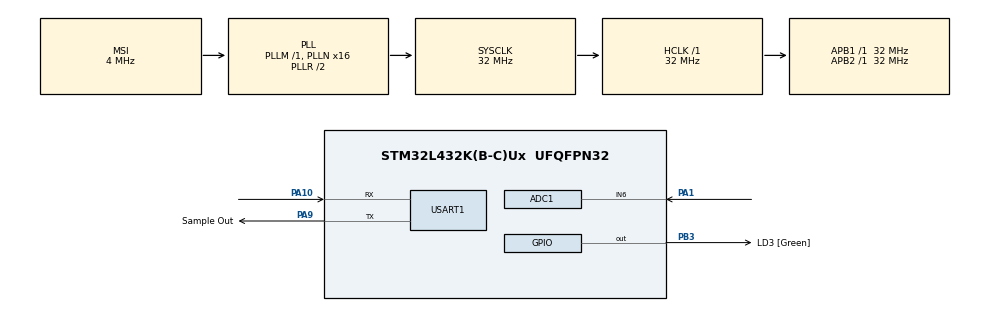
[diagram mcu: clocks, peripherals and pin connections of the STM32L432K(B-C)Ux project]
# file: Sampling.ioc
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ADC1.Channel-0\#ChannelRegularConversion=ADC_CHANNEL_6
ADC1.ExternalTrigConv=ADC_EXTERNALTRIG_T2_TRGO
ADC1.NbrOfConversionFlag=1
ADC1.OffsetNumber-0\#ChannelRegularConversion=ADC_OFFSET_NONE
ADC1.Rank-0\#ChannelRegularConversion=1
ADC1.Resolution=ADC_RESOLUTION_8B
ADC1.SamplingTime-0\#ChannelRegularConversion=ADC_SAMPLETIME_2CYCLES_5
ADC1.master=1
Mcu.Family=STM32L4
Mcu.Name=STM32L432K(B-C)Ux
Mcu.Package=UFQFPN32
NVIC.ADC1_IRQn=true\:0\:0\:false\:false\:true\:true\:true\:true
NVIC.PriorityGroup=NVIC_PRIORITYGROUP_4
NVIC.TIM2_IRQn=true\:0\:0\:false\:false\:true\:true\:true\:true
NVIC.USART1_IRQn=true\:0\:0\:false\:false\:true\:true\:true\:true
PA0.GPIO_Label=MCO [High speed clock in]
PA0.Mode=HSE-External-Clock-Source-for-LittleOrca
PA0.Signal=RCC_CK_IN
PA1.Signal=ADCx_IN6
PA10.Mode=Asynchronous
PA10.Signal=USART1_RX
PA13\ (JTMS-SWDIO).GPIO_Label=SWDIO
PA13\ (JTMS-SWDIO).Mode=Serial_Wire
PA13\ (JTMS-SWDIO).Signal=SYS_JTMS-SWDIO
PA14\ (JTCK-SWCLK).GPIO_Label=SWCLK
PA14\ (JTCK-SWCLK).Mode=Serial_Wire
PA14\ (JTCK-SWCLK).Signal=SYS_JTCK-SWCLK
PA15\ (JTDI).GPIO_Label=VCP_RX
PA15\ (JTDI).Signal=USART2_RX
PA2.GPIO_Label=VCP_TX
PA2.Signal=USART2_TX
PA9.GPIO_Label=Sample Out
PA9.Mode=Asynchronous
PA9.Signal=USART1_TX
PB3\ (JTDO-TRACESWO).GPIO_Label=LD3 [Green]
PB3\ (JTDO-TRACESWO).Signal=GPIO_Output
PC14-OSC32_IN\ (PC14).Mode=LSE-External-Oscillator
PC14-OSC32_IN\ (PC14).Signal=RCC_OSC32_IN
PC15-OSC32_OUT\ (PC15).Mode=LSE-External-Oscillator
PC15-OSC32_OUT\ (PC15).Signal=RCC_OSC32_OUT
ProjectManager.HeapSize=0x200
ProjectManager.StackSize=0x400
ProjectManager.TargetToolchain=STM32CubeIDE
RCC.ADCFreq_Value=32000000
RCC.AHBFreq_Value=32000000
RCC.APB1Freq_Value=32000000
RCC.APB1TimFreq_Value=32000000
RCC.APB2Freq_Value=32000000
RCC.APB2TimFreq_Value=32000000
RCC.CortexFreq_Value=32000000
RCC.HCLKFreq_Value=32000000
RCC.HSE_VALUE=8000000
RCC.HSI16_VALUE=16000000
RCC.HSI48_VALUE=48000000
RCC.HSI_VALUE=16000000
RCC.MSI_VALUE=4000000
RCC.PLLMUL=RCC_PLLMUL_4
RCC.PLLN=16
RCC.PLLSAI1N=16
RCC.SYSCLKFreq_VALUE=32000000
RCC.SYSCLKSource=RCC_SYSCLKSOURCE_PLLCLK
RCC.USBFreq_Value=32000000
RCC.VCOOutputFreq_Value=64000000
SH.ADCx_IN6.0=ADC1_IN6,IN6-Single-Ended
TIM2.Period=19
TIM2.Prescaler=719
TIM2.TIM_MasterOutputTrigger=TIM_TRGO_UPDATE
USART1.VirtualMode-Asynchronous=VM_ASYNC
VP_TIM2_VS_ClockSourceINT.Mode=Internal
board=NUCLEO-L432KC

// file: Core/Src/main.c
/* USER CODE BEGIN Header */
/**
  ******************************************************************************
  * @file           : main.c
  * @brief          : Main program body
  ******************************************************************************
  * @attention
  *
  * Copyright (c) 2025 STMicroelectronics.
  * All rights reserved.
  *
  * This software is licensed under terms that can be found in the LICENSE file
  * in the root directory of this software component.
  * If no LICENSE file comes with this software, it is provided AS-IS.
  *
  ******************************************************************************
  */
/* USER CODE END Header */
#include "main.h"

ADC_HandleTypeDef hadc1;

TIM_HandleTypeDef htim2;

UART_HandleTypeDef huart1;

void SystemClock_Config(void);
static void MX_GPIO_Init(void);
static void MX_TIM2_Init(void);
static void MX_ADC1_Init(void);
static void MX_USART1_UART_Init(void);

int main(void)
{

  /* MCU Configuration--------------------------------------------------------*/

  /* Reset of all peripherals, Initializes the Flash interface and the Systick. */
  HAL_Init();

  /* Configure the system clock */
  SystemClock_Config();

  /* Initialize all configured peripherals */
  MX_GPIO_Init();
  MX_TIM2_Init();
  MX_ADC1_Init();
  MX_USART1_UART_Init();
  /* USER CODE BEGIN 2 */
    HAL_TIM_Base_Start(&htim2);
    HAL_ADC_Start_IT(&hadc1);
  /* USER CODE END 2 */

  /* Infinite loop */
    while (1) {

    }
}

void SystemClock_Config(void)
{
  RCC_OscInitTypeDef RCC_OscInitStruct = {0};
  RCC_ClkInitTypeDef RCC_ClkInitStruct = {0};

  /** Configure the main internal regulator output voltage
  */
  if (HAL_PWREx_ControlVoltageScaling(PWR_REGULATOR_VOLTAGE_SCALE1) != HAL_OK)
  {
    Error_Handler();
  }

  /** Configure LSE Drive Capability
  */
  HAL_PWR_EnableBkUpAccess();
  __HAL_RCC_LSEDRIVE_CONFIG(RCC_LSEDRIVE_LOW);

  /** Initializes the RCC Oscillators according to the specified parameters
  * in the RCC_OscInitTypeDef structure.
  */
  RCC_OscInitStruct.OscillatorType = RCC_OSCILLATORTYPE_LSE|RCC_OSCILLATORTYPE_MSI;
  RCC_OscInitStruct.LSEState = RCC_LSE_ON;
  RCC_OscInitStruct.MSIState = RCC_MSI_ON;
  RCC_OscInitStruct.MSICalibrationValue = 0;
  RCC_OscInitStruct.MSIClockRange = RCC_MSIRANGE_6;
  RCC_OscInitStruct.PLL.PLLState = RCC_PLL_ON;
  RCC_OscInitStruct.PLL.PLLSource = RCC_PLLSOURCE_MSI;
  RCC_OscInitStruct.PLL.PLLM = 1;
  RCC_OscInitStruct.PLL.PLLN = 16;
  RCC_OscInitStruct.PLL.PLLP = RCC_PLLP_DIV7;
  RCC_OscInitStruct.PLL.PLLQ = RCC_PLLQ_DIV2;
  RCC_OscInitStruct.PLL.PLLR = RCC_PLLR_DIV2;
  if (HAL_RCC_OscConfig(&RCC_OscInitStruct) != HAL_OK)
  {
    Error_Handler();
  }

  /** Initializes the CPU, AHB and APB buses clocks
  */
  RCC_ClkInitStruct.ClockType = RCC_CLOCKTYPE_HCLK|RCC_CLOCKTYPE_SYSCLK
                              |RCC_CLOCKTYPE_PCLK1|RCC_CLOCKTYPE_PCLK2;
  RCC_ClkInitStruct.SYSCLKSource = RCC_SYSCLKSOURCE_PLLCLK;
  RCC_ClkInitStruct.AHBCLKDivider = RCC_SYSCLK_DIV1;
  RCC_ClkInitStruct.APB1CLKDivider = RCC_HCLK_DIV1;
  RCC_ClkInitStruct.APB2CLKDivider = RCC_HCLK_DIV1;

  if (HAL_RCC_ClockConfig(&RCC_ClkInitStruct, FLASH_LATENCY_1) != HAL_OK)
  {
    Error_Handler();
  }

  /** Enable MSI Auto calibration
  */
  HAL_RCCEx_EnableMSIPLLMode();
}

static void MX_ADC1_Init(void)
{

  ADC_ChannelConfTypeDef sConfig = {0};

  /** Common config
  */
  hadc1.Instance = ADC1;
  hadc1.Init.ClockPrescaler = ADC_CLOCK_ASYNC_DIV1;
  hadc1.Init.Resolution = ADC_RESOLUTION_8B;
  hadc1.Init.DataAlign = ADC_DATAALIGN_RIGHT;
  hadc1.Init.ScanConvMode = ADC_SCAN_DISABLE;
  hadc1.Init.EOCSelection = ADC_EOC_SINGLE_CONV;
  hadc1.Init.LowPowerAutoWait = DISABLE;
  hadc1.Init.ContinuousConvMode = DISABLE;
  hadc1.Init.NbrOfConversion = 1;
  hadc1.Init.DiscontinuousConvMode = DISABLE;
  hadc1.Init.ExternalTrigConv = ADC_EXTERNALTRIG_T2_TRGO;
  hadc1.Init.ExternalTrigConvEdge = ADC_EXTERNALTRIGCONVEDGE_RISING;
  hadc1.Init.DMAContinuousRequests = DISABLE;
  hadc1.Init.Overrun = ADC_OVR_DATA_PRESERVED;
  hadc1.Init.OversamplingMode = DISABLE;
  if (HAL_ADC_Init(&hadc1) != HAL_OK)
  {
    Error_Handler();
  }

  /** Configure Regular Channel
  */
  sConfig.Channel = ADC_CHANNEL_6;
  sConfig.Rank = ADC_REGULAR_RANK_1;
  sConfig.SamplingTime = ADC_SAMPLETIME_2CYCLES_5;
  sConfig.SingleDiff = ADC_SINGLE_ENDED;
  sConfig.OffsetNumber = ADC_OFFSET_NONE;
  sConfig.Offset = 0;
  if (HAL_ADC_ConfigChannel(&hadc1, &sConfig) != HAL_OK)
  {
    Error_Handler();
  }

}

static void MX_TIM2_Init(void)
{

  TIM_ClockConfigTypeDef sClockSourceConfig = {0};
  TIM_MasterConfigTypeDef sMasterConfig = {0};

  htim2.Instance = TIM2;
  htim2.Init.Prescaler = 719;
  htim2.Init.CounterMode = TIM_COUNTERMODE_UP;
  htim2.Init.Period = 19;
  htim2.Init.ClockDivision = TIM_CLOCKDIVISION_DIV1;
  htim2.Init.AutoReloadPreload = TIM_AUTORELOAD_PRELOAD_DISABLE;
  if (HAL_TIM_Base_Init(&htim2) != HAL_OK)
  {
    Error_Handler();
  }
  sClockSourceConfig.ClockSource = TIM_CLOCKSOURCE_INTERNAL;
  if (HAL_TIM_ConfigClockSource(&htim2, &sClockSourceConfig) != HAL_OK)
  {
    Error_Handler();
  }
  sMasterConfig.MasterOutputTrigger = TIM_TRGO_UPDATE;
  sMasterConfig.MasterSlaveMode = TIM_MASTERSLAVEMODE_DISABLE;
  if (HAL_TIMEx_MasterConfigSynchronization(&htim2, &sMasterConfig) != HAL_OK)
  {
    Error_Handler();
  }

}

static void MX_USART1_UART_Init(void)
{

  huart1.Instance = USART1;
  huart1.Init.BaudRate = 115200;
  huart1.Init.WordLength = UART_WORDLENGTH_8B;
  huart1.Init.StopBits = UART_STOPBITS_1;
  huart1.Init.Parity = UART_PARITY_NONE;
  huart1.Init.Mode = UART_MODE_TX_RX;
  huart1.Init.HwFlowCtl = UART_HWCONTROL_NONE;
  huart1.Init.OverSampling = UART_OVERSAMPLING_16;
  huart1.Init.OneBitSampling = UART_ONE_BIT_SAMPLE_DISABLE;
  huart1.AdvancedInit.AdvFeatureInit = UART_ADVFEATURE_NO_INIT;
  if (HAL_UART_Init(&huart1) != HAL_OK)
  {
    Error_Handler();
  }

}

static void MX_GPIO_Init(void)
{
  GPIO_InitTypeDef GPIO_InitStruct = {0};

  /* GPIO Ports Clock Enable */
  __HAL_RCC_GPIOC_CLK_ENABLE();
  __HAL_RCC_GPIOA_CLK_ENABLE();
  __HAL_RCC_GPIOB_CLK_ENABLE();

  /*Configure GPIO pin Output Level */
  HAL_GPIO_WritePin(LD3_GPIO_Port, LD3_Pin, GPIO_PIN_RESET);

  /*Configure GPIO pin : VCP_TX_Pin */
  GPIO_InitStruct.Pin = VCP_TX_Pin;
  GPIO_InitStruct.Mode = GPIO_MODE_AF_PP;
  GPIO_InitStruct.Pull = GPIO_NOPULL;
  GPIO_InitStruct.Speed = GPIO_SPEED_FREQ_VERY_HIGH;
  GPIO_InitStruct.Alternate = GPIO_AF7_USART2;
  HAL_GPIO_Init(VCP_TX_GPIO_Port, &GPIO_InitStruct);

  /*Configure GPIO pin : VCP_RX_Pin */
  GPIO_InitStruct.Pin = VCP_RX_Pin;
  GPIO_InitStruct.Mode = GPIO_MODE_AF_PP;
  GPIO_InitStruct.Pull = GPIO_NOPULL;
  GPIO_InitStruct.Speed = GPIO_SPEED_FREQ_VERY_HIGH;
  GPIO_InitStruct.Alternate = GPIO_AF3_USART2;
  HAL_GPIO_Init(VCP_RX_GPIO_Port, &GPIO_InitStruct);

  /*Configure GPIO pin : LD3_Pin */
  GPIO_InitStruct.Pin = LD3_Pin;
  GPIO_InitStruct.Mode = GPIO_MODE_OUTPUT_PP;
  GPIO_InitStruct.Pull = GPIO_NOPULL;
  GPIO_InitStruct.Speed = GPIO_SPEED_FREQ_LOW;
  HAL_GPIO_Init(LD3_GPIO_Port, &GPIO_InitStruct);

}

/* USER CODE BEGIN 4 */

void HAL_ADC_ConvCpltCallback(ADC_HandleTypeDef *hadc) {
    uint8_t sampledValue = HAL_ADC_GetValue(&hadc1);
    if (sampledValue > 155) {
        HAL_GPIO_WritePin(LD3_GPIO_Port, LD3_Pin, GPIO_PIN_SET);
    } else {
        HAL_GPIO_WritePin(LD3_GPIO_Port, LD3_Pin, GPIO_PIN_RESET);
    }
    // HAL_UART_Transmit(&huart1, &sampledValue, 1, HAL_MAX_DELAY);
}

/* USER CODE END 4 */

void Error_Handler(void)
{
    __disable_irq();
    while (1) {
    }
}
